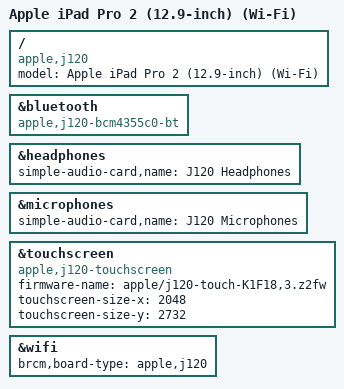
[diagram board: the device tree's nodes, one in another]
// SPDX-License-Identifier: GPL-2.0+ OR MIT
/*
 * Apple iPad Pro 2 (12.9-inch) (Wi-Fi), J120, iPad7,1 (A1670)
 * Copyright (c) 2022, Konrad Dybcio <konradybcio@kernel.org>
 */

/dts-v1/;

#include "t8011.dtsi"
#include "t8011-common.dtsi"
#include "t8011-pro2.dtsi"

/ {
	compatible = "apple,j120", "apple,t8011", "apple,arm-platform";
	model = "Apple iPad Pro 2 (12.9-inch) (Wi-Fi)";
};

&bluetooth {
	compatible = "apple,j120-bcm4355c0-bt", "brcm,bcm4355c0-bt";
};

&headphones {
	simple-audio-card,name = "J120 Headphones";
};

&microphones {
	simple-audio-card,name = "J120 Microphones";
};

/* Touch personality K1F18,3 (ADT multi-touch hid-merge-personality) */
&touchscreen {
	compatible = "apple,j120-touchscreen";
	firmware-name = "apple/j120-touch-K1F18,3.z2fw";
	touchscreen-size-x = <2048>;
	touchscreen-size-y = <2732>;
};

&wifi {
	brcm,board-type = "apple,j120";
};
